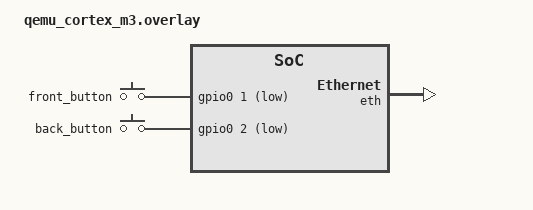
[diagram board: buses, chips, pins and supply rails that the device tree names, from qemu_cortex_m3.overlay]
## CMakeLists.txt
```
# SPDX-License-Identifier: Apache-2.0

cmake_minimum_required(VERSION 3.20.0)

set(ZEPHYR_EXTRA_MODULES "${CMAKE_CURRENT_SOURCE_DIR}/camera_service/")

find_package(Zephyr REQUIRED HINTS $ENV{ZEPHYR_BASE})

project(projeto_radar)

zephyr_include_directories(include/)

list(APPEND ZEPHYR_EXTRA_MODULES ${CMAKE_CURRENT_SOURCE_DIR}/src)

target_sources(app PRIVATE src/main.c src/display.c src/sensor.c src/system_thread.c)
```

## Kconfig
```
menu "Zephyr"
  source "Kconfig.zephyr"
endmenu

config DUMMY_DISPLAY
	bool "Dummy display driver"
	default y
	depends on DT_HAS_ZEPHYR_DUMMY_DC_ENABLED
	help
	  Enable dummy display driver compliant with display driver API.

menu "dev"
  config SIM_CAR_PASSAGE
      bool "Simular passagem de carro"
      default y
      help
        Habilita a simulação de passagem de carro.

  config TEST_SNTP
      bool "Testar SNTP"
      default n
      help
        Habilita o teste do SNTP.

  config SNTP_SERVER_ADDRESS
    string "SNTP server address"
    default "a.st1.ntp.br"

  config SNTP_SERVER_PORT
    int "SNTP server port"
    default 123

  config SNTP_SERVER_TIMEOUT_MS
    int "Duration to wait for response"
    default 1000

endmenu

menu "Radar Configuration"

  config RADAR_SENSOR_DISTANCE_MM
      int "Distância entre sensores (mm)"
      default 5000
      help
        Define a distância física em milímetros entre os dois sensores magnéticos.

  config RADAR_SPEED_LIMIT_KMH
      int "Limite de velocidade (km/h)"
      default 60
      help
        Define o limite de velocidade em km/h para detecção de infrações.

  config SIMULATE_PROCESSING_TIME
      bool "Simular tempo de processamento"
      default y
      help
        Habilita a simulação do tempo de processamento de componentes.
  
  config RADAR_PROCESSING_TIME_MS
      int "Tempo de processamento (ms)"
      default 500
      depends on SIMULATE_PROCESSING_TIME
      help
        Define o tempo de processamento em milissegundos para simulação.

endmenu
```

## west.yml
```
manifest:
  remotes:
    - name: zephyrproject-rtos
      url-base: https://github.com/zephyrproject-rtos
  projects:
    - name: zephyr
      remote: zephyrproject-rtos
      clone-depth: 1
      revision: v4.1.0
path: projeto_radar
```

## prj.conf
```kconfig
CONFIG_GPIO=y
CONFIG_ZBUS=y
CONFIG_DUMMY_DISPLAY=y
CONFIG_AUXDISPLAY=y
CONFIG_DISPLAY=y
CONFIG_ZBUS_MSG_SUBSCRIBER=y
CONFIG_QEMU_ICOUNT=n

CONFIG_CBPRINTF_FP_SUPPORT=y

# == RANDOM NUMBER GENERATOR ==
CONFIG_ENTROPY_GENERATOR=y
CONFIG_TEST_RANDOM_GENERATOR=y
# == == == == ==

CONFIG_LOG_BACKEND_UART=y
CONFIG_LOG=y
CONFIG_LOG_DEFAULT_LEVEL=3
CONFIG_LOG_MODE_DEFERRED=y
CONFIG_PRINTK=y

# ===== NETWORKING BASE =====
CONFIG_NETWORKING=y
CONFIG_NET_CONNECTION_MANAGER=y
CONFIG_NET_SOCKETS=y
CONFIG_NET_IPV4=y
CONFIG_NET_IPV6=y
CONFIG_NET_QEMU_ETHERNET=y
CONFIG_NET_QEMU_USER=y

# ===== NETWORK PROTOCOLS =====
CONFIG_NET_UDP=y
CONFIG_NET_TCP=y
CONFIG_SNTP=y
CONFIG_NET_SOCKETS_POLL_MAX=5

# ===== NETWORK INTERFACE CONFIGURATION =====
CONFIG_NET_CONFIG_SETTINGS=y
CONFIG_NET_CONFIG_AUTO_INIT=y
CONFIG_NET_CONFIG_NEED_IPV4=y
CONFIG_NET_DHCPV4=y
CONFIG_NET_DHCPV6=y
# CONFIG_NET_CONFIG_MY_IPV4_ADDR="192.168.0.100"
# CONFIG_NET_CONFIG_MY_IPV4_NETMASK="255.255.255.0"
# CONFIG_NET_CONFIG_MY_IPV4_GW="192.168.0.1"

# ===== ETHERNET CONFIGURATION =====
CONFIG_NET_L2_ETHERNET=y
CONFIG_ETH_STELLARIS=y
CONFIG_NET_SLIP_TAP=n

# ===== DNS CONFIGURATION =====
CONFIG_DNS_RESOLVER=y
CONFIG_DNS_SERVER_IP_ADDRESSES=y
CONFIG_DNS_SERVER1="8.8.8.8"

# ===== NETWORK BUFFERS =====
CONFIG_NET_BUF_RX_COUNT=16
CONFIG_NET_BUF_TX_COUNT=16
CONFIG_NET_PKT_RX_COUNT=16
CONFIG_NET_PKT_TX_COUNT=16
CONFIG_NET_CONTEXT_NET_PKT_POOL=y

# ===== NETWORK MANAGEMENT =====
CONFIG_NET_MGMT=y
CONFIG_NET_MGMT_EVENT=y
CONFIG_NET_MGMT_EVENT_INFO=y

# === CONFIG RETIRADA DO PROJETO SNTP CLIENT ===
# General config
# CONFIG_REQUIRES_FULL_LIBC=y
# CONFIG_POSIX_API=y




CONFIG_REQUIRES_FULL_LIBC=y

CONFIG_MAIN_STACK_SIZE=2048
# # Network debug config
# CONFIG_NET_LOG=y
# CONFIG_LOG=y
# CONFIG_NET_SOCKETS_LOG_LEVEL_DBG=n
# CONFIG_SNTP_LOG_LEVEL_DBG=n


# Habilite a interface Ethernet do QEMU
# CONFIG_NET_QEMU_ETHERNET=y
```

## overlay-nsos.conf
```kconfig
# Copyright (c) 2025 Embeint Inc

CONFIG_ETH_NATIVE_TAP=n
CONFIG_NET_DRIVERS=y
CONFIG_NET_SOCKETS=y
CONFIG_NET_SOCKETS_OFFLOAD=y
CONFIG_NET_NATIVE_OFFLOADED_SOCKETS=y
CONFIG_HEAP_MEM_POOL_SIZE=4096

# IPv6 DAD requires lower level network interface access, below exposed socket-level access
CONFIG_NET_IPV6_DAD=n
```

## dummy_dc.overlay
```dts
/*
 * Copyright (c) 2021 Nordic Semiconductor ASA
 *
 * SPDX-License-Identifier: Apache-2.0
 */

/ {
	chosen {
		zephyr,display = &dummy_dc;
	};

	dummy_dc: dummy_dc {
		compatible = "zephyr,dummy-dc";
		height = <240>;
		width = <320>;
	};
};
```

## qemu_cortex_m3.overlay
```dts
#include <zephyr/dt-bindings/gpio/gpio.h>

/ {
	
	aliases {
		sw0 = &front_button;
		sw1 = &back_button;
	};

	buttons {
		compatible = "gpio-keys";
		debounce-interval-ms = <30>;

		front_button: button_0 {
			gpios = <&gpio0 1 GPIO_ACTIVE_LOW>;
		};
		back_button: button_1 {
			gpios = <&gpio0 2 GPIO_ACTIVE_LOW>;
		};
	};

	chosen {
		zephyr,display = &dummy_dc;
	};

	dummy_dc: dummy_dc {
		compatible = "zephyr,dummy-dc";
		height = <240>;
		width = <320>;
		
	};


};

&gpio0 {
    status = "okay";
    compatible = "zephyr,gpio-emul";
    rising-edge;
    falling-edge;
    high-level;
    low-level;
    gpio-controller;
    #gpio-cells = < 0x2 >;
    phandle = < 0x1 >;
};

&eth {
    status = "okay";
};
```

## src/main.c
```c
#include "main.h"
#include "sensor.h"
#include "camera_service.h"
#include "display.h"

#include <stdio.h>
#include <zephyr/kernel.h>
#include <zephyr/logging/log.h>
#include <zephyr/zbus/zbus.h>
#include <string.h>
#include <zephyr/drivers/gpio/gpio_emul.h>
#include <zephyr/random/random.h>
#include <zephyr/drivers/auxdisplay.h>
#include <zephyr/device.h>

#ifdef CONFIG_SNTP
#include <zephyr/net/sntp.h>
#include <zephyr/net/socket.h>
#endif

LOG_MODULE_REGISTER(system);

#define SYSTEM_THREAD_STACK_SIZE 1024
#define NETWORK_THREAD_STACK_SIZE 1024

#define SYSTEM_THREAD_PRIORITY 2
#define NETWORK_THREAD_PRIORITY 4

K_THREAD_STACK_DEFINE(system_stack, SYSTEM_THREAD_STACK_SIZE);
K_THREAD_STACK_DEFINE(network_stack, NETWORK_THREAD_STACK_SIZE);

/*
    NTP to UTC Implementation by Matt
    at https://stackoverflow.com/questions/5206857/convert-ntp-timestamp-to-utc

    NTP_TIMESTAMP_DIFF - The difference in seconds between the NTP epoch (1900) and the Unix epoch (1970).
    NTP_MAX_INT_AS_DOUBLE - The maximum value of the fractional part of an NTP timestamp, which is 2^32 - 1.
*/
#define NTP_TIMESTAMP_DIFF     (2208988800)
#define NTP_MAX_INT_AS_DOUBLE  (4294967295.0)

#define TIMEZONE_OFFSET_SECONDS (-3 * 3600)

ZBUS_MSG_SUBSCRIBER_DEFINE(network_subscriber);
ZBUS_CHAN_ADD_OBS(network_chan, network_subscriber, 3);

/*
    @brief Converts SNTP time to a struct tm in Brazil's timezone and formats it as a string.
    @param tm_brazil Pointer to a struct tm to store the converted time.
    @param time_str Pointer to a string buffer to store the formatted time.
    @return 0 on success, negative error code on failure.
*/
int get_converted_sntp_time(struct tm *tm_brazil, char *time_str)
{
    struct sntp_time ts;
    int rc;
#ifdef CONFIG_SNTP_SERVER_ADDRESS
    const char *ntp_server = CONFIG_SNTP_SERVER_ADDRESS;
#else
    const char *ntp_server = "pool.ntp.org:123";
#endif

#ifdef CONFIG_SNTP_SERVER_TIMEOUT_MS
    const int timeout_ms = CONFIG_SNTP_SERVER_TIMEOUT_MS;
#else
    const int timeout_ms = 5000; 
#endif


    rc = sntp_simple(ntp_server, timeout_ms, &ts);
    if (rc == 0) {

        time_t unix_time;

        if (ts.seconds < NTP_TIMESTAMP_DIFF) {

            unix_time = (time_t)ts.seconds;
        } else {
            unix_time = (time_t)(ts.seconds - NTP_TIMESTAMP_DIFF);
        }       
        time_t datetime = unix_time + TIMEZONE_OFFSET_SECONDS;

        struct tm *_tm_brazil = gmtime(&datetime);
        if (_tm_brazil) {
            char _time_str[49];
            strftime(_time_str, 48, "[%Y-%m-%d %H:%M:%S]", _tm_brazil);

            if (time_str != NULL) {
                strcpy(time_str, _time_str);
                time_str[48] = '\0';
            }
            
            if (tm_brazil != NULL) {
                *tm_brazil = *_tm_brazil;
            }
            

            return 0;

        } else {
            return -1;
        }

    } else {
        return rc;
    }
}

static void network_thread(void *arg1, void *arg2, void *arg3) {
    ARG_UNUSED(arg1);
    ARG_UNUSED(arg2);
    ARG_UNUSED(arg3);

    while (1) {
        struct network_event_t data;
        const struct zbus_channel *chan;

        /*
            When the system thread identifies a violation, it will publish a request
            in the network channel.
        */
        if (!zbus_sub_wait_msg(&network_subscriber, &chan, &data, K_FOREVER)) {
            switch (data.type) {
                case NETWORK_EVENT_SNTP_REQUEST: {
                    struct tm tm_brazil;
                    char time_str[49];
                    int ret = get_converted_sntp_time(&tm_brazil, time_str);

                    data = (struct network_event_t) {
                        .type = NETWORK_EVENT_SNTP_RESPONSE,
                        .sntp_response = {
                            .unix_time = mktime(&tm_brazil),
                            .time_str = time_str,
                            .error_code = ret
                        }
                    };

                    int err = zbus_chan_pub(&network_chan, &data, K_NO_WAIT);

                    if (err) {
                        LOG_ERR("Failed to publish SNTP response: %d", err);
                    }

                    break;
                }
                
                default:
                    LOG_WRN("Unknown network event type: %d", data.type);
                    break;
            }
        }
    }
}

#if CONFIG_TEST_SNTP

void test_sntp(void)
{

    char time_str[49];
    int ret = get_converted_sntp_time(NULL, time_str);

    if (ret == 0) {
        LOG_INF("SNTP Converted Time: %s", time_str);
    } else {
        LOG_ERR("Failed to get SNTP time: %d", ret);
    }
    
}
#endif

void sim_car_pass(void)
{
    int random_delay = sys_rand32_get() % 300 + 100;

    LOG_INF("Delay aleatório: %d ms", random_delay);

    LOG_INF("Carro passando...");
    gpio_emul_input_set(sensor1.port, sensor1.pin, 1);
    k_msleep(2);
    gpio_emul_input_set(sensor1.port, sensor1.pin, 0);

    k_msleep(random_delay);

    gpio_emul_input_set(sensor2.port, sensor2.pin, 1);
    k_msleep(2);
    gpio_emul_input_set(sensor2.port, sensor2.pin, 0);

    LOG_INF("Carro passou!");
    k_msleep(300);
}

int main(void) {

    /*
    Waits for the system to be ready before starting simulation.
    */
    k_msleep(1000);

    LOG_INF("Sistema inicializado!");
    uint8_t sim_times = 5;

    while (1) {
#ifdef CONFIG_SIM_CAR_PASSAGE
        if (CONFIG_SIM_CAR_PASSAGE) {
            if (sim_times > 0) sim_car_pass();

            if (sim_times == 0) {
                break;
            }

            sim_times--;
        }
#endif
        #if CONFIG_TEST_SNTP
        test_sntp();
        #endif

        k_msleep(500);
    }
}

ZBUS_CHAN_DEFINE(network_chan, struct network_event_t, NULL, NULL, ZBUS_OBSERVERS_EMPTY, ZBUS_MSG_INIT(.type = NETWORK_EVENT_SNTP_RESPONSE, .sntp_response = {.unix_time = 0, .error_code = 0}));
K_THREAD_DEFINE(network_thread_id, SYSTEM_THREAD_STACK_SIZE, network_thread, NULL, NULL, NULL, SYSTEM_THREAD_PRIORITY, 0, 0);
```

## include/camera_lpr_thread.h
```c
#ifndef CAMERA_LPR_THREAD_H
#define CAMERA_LPR_THREAD_H

void camera_lpr_thread(void);

#endif // CAMERA_LPR_THREAD_H
```

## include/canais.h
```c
#ifndef CANAIS_H
#define CANAIS_H
#include <zephyr/zbus/zbus.h>

struct velocidade_evento_t {
    float velocidade_kmh;
    uint32_t event_id;
};

ZBUS_CHAN_DECLARE(velocidade_chan);

#endif
```

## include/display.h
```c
#ifndef _DISPLAY_H_
#define _DISPLAY_H_

#include <zephyr/zbus/zbus.h>

struct display_data_t {
    int brightness;
    int contrast;
    char text[128];
};

ZBUS_CHAN_DECLARE(display_chan);

#endif
```

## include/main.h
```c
#ifndef MAIN_H
#define MAIN_H

#include <zephyr/kernel.h>
#include <zephyr/zbus/zbus.h>
#include <time.h>

enum network_event_type {
    NETWORK_EVENT_SNTP_RESPONSE,
    NETWORK_EVENT_HTTP_RESPONSE,
    NETWORK_EVENT_SNTP_REQUEST,
    NETWORK_EVENT_HTTP_REQUEST,
    NETWORK_EVENT_ERROR,
};

struct network_event_t {
    enum network_event_type type;
    union {
        struct {
            time_t unix_time;
            char time_str[49];
            int error_code;
        } sntp_response;

        struct {
            int status_code;
            char *response;
        } http_response;

        struct {
            char *request_url;
            int timeout_ms;
        } http_request;
    };
};

int get_converted_sntp_time(struct tm *tm_brazil, char *time_str);

ZBUS_CHAN_DECLARE(network_chan);

#endif
```

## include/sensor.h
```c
#ifndef _SENSOR_H_
#define _SENSOR_H_

#include <stdint.h>
#include <zephyr/drivers/gpio.h>
#include <zephyr/zbus/zbus.h>

struct sensor_result {
    uint32_t timestamp_sensor1;
    uint32_t timestamp_sensor2;
    float velocidade_kmh;
};

// Torna sensor1 e sensor2 acessíveis globalmente
extern const struct gpio_dt_spec sensor1;
extern const struct gpio_dt_spec sensor2;

void sensor_thread(void *arg1, void *arg2, void *arg3);

// Função de cálculo de velocidade (pode ser usada em testes)
int calcular_velocidade_kmh(uint32_t t1_ms, uint32_t t2_ms, float distancia_m, float *velocidade_ptr);

struct velocidade_evento_t {
    float velocidade_kmh;
    uint32_t event_id;
};

struct sensor_evento_t {
    uint32_t timestamp_sensor1;
    uint32_t timestamp_sensor2;
};

ZBUS_CHAN_DECLARE(velocidade_chan);
ZBUS_CHAN_DECLARE(sensor_chan);

#endif
```

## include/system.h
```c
#ifndef SYSTEM_H
#define SYSTEM_H

void system_start(void);
void print_log(const char *message);
void init_threads(void);

#endif // SYSTEM_H
```

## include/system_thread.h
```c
#ifndef SYSTEM_THREAD_H
#define SYSTEM_THREAD_H

#include <time.h>


#define PLACA_BRASIL        "Brasil [LLL N L NN]"
#define PLACA_ARGENTINA     "Argentina [LL NNN LL]"
#define PLACA_PARAGUAI_CARRO "Paraguai (Carro) [LLLL NNN]"
#define PLACA_PARAGUAI_MOTO  "Paraguai (Moto) [NNN LLLL]"
#define PLACA_URUGUAI       "Uruguai [LLL NNNN]"
#define PLACA_BOLIVIA       "Bolivia [LL NNNNN]"

void system_thread(void *arg1, void *arg2, void *arg3);
bool validar_placa_mercosul(const char *placa, char *padrao);

#endif // SYSTEM_THREAD_H
```

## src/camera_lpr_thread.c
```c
#include <zephyr/kernel.h>
#include <zephyr/zbus/zbus.h>
#include <zephyr/sys/util.h>
#include <zephyr/logging/log.h>
#include "camera_lpr_thread.h"
#include <zephyr/random/random.h>

LOG_MODULE_REGISTER(camera_lpr);

// Definição dos canais ZBUS para trigger e resultado
ZBUS_CHAN_DEFINE(lpr_trigger_chan,         // nome do canal
                 int,                      // tipo de dado
                 NULL,                     // validator
                 NULL,                     // user_data
                 ZBUS_OBSERVERS_EMPTY,     // observers
                 ZBUS_MSG_INIT(0));        // valor inicial

struct lpr_result_t {
    char placa[16];
    char hash[32];
    bool valida;
};

ZBUS_CHAN_DEFINE(lpr_result_chan,
                 struct lpr_result_t,
                 NULL,
                 NULL,
                 ZBUS_OBSERVERS_EMPTY,
                 ZBUS_MSG_INIT(.placa = "", .hash = "", .valida = false));

#define LPR_STACK_SIZE 2048
#define LPR_PRIORITY 5

static void gerar_placa(char *placa, bool *valida) {
    uint32_t rand_val = sys_rand32_get();
    uint8_t fail_chance = rand_val % 100;
    if (fail_chance < CONFIG_RADAR_CAMERA_FAILURE_RATE_PERCENT) {
        // Placa inválida (falha simulada)
        placa[0] = '\0';
        *valida = false;
        LOG_INF("Falha simulada na câmera LPR");
        printk("Falha simulada na câmera LPR\n");
    } else {
        strcpy(placa, "BRA2E19"); // Exemplo Mercosul válida
        *valida = true;
    }
}

static void gerar_hash_foto(char *hash) {
    strcpy(hash, "HASH_PLACEHOLDER");
}

void camera_lpr_thread(void)
{
    while (1) {
        // Aguarda trigger via ZBUS
        int trigger;
        int ret = zbus_chan_read(&lpr_trigger_chan, &trigger, K_FOREVER);
        if (ret == 0 && trigger) {
            // Simula tempo de processamento caso habilitado
            if (CONFIG_SIMULATE_PROCESSING_TIME)
            {
                k_msleep(CONFIG_RADAR_PROCESSING_TIME_MS);
            }

            // Gera placa e hash
            char placa[16];
            char hash[32];
            bool valida;
            gerar_placa(placa, &valida);
            gerar_hash_foto(hash);

            struct {
                char placa[16];
                char hash[32];
                bool valida;
            } resultado;

            strcpy(resultado.placa, placa);
            strcpy(resultado.hash, hash);
            resultado.valida = valida;

            // Publica resultado no canal ZBUS
            zbus_chan_pub(&lpr_result_chan, &resultado, K_NO_WAIT);
        }
        // else: ignora triggers inválidos ou erros de leitura
    }
}

K_THREAD_DEFINE(camera_lpr_tid, LPR_STACK_SIZE, camera_lpr_thread, NULL, NULL, NULL, LPR_PRIORITY, 0, 0);
```

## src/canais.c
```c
#include <zephyr/zbus/zbus.h>
#include "canais.h"

// Inicializa o canal com zeros
ZBUS_CHAN_DEFINE(velocidade_chan, struct velocidade_evento_t, NULL, NULL, ZBUS_OBSERVERS_EMPTY, ZBUS_MSG_INIT(.velocidade_kmh = 0.0f, .event_id = 0));
```

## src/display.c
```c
#include "display.h"

#include <zephyr/kernel.h>
#include <zephyr/logging/log.h>
#include <zephyr/zbus/zbus.h>
#include <zephyr/drivers/auxdisplay.h>
// #include <zephyr/drivers/display.h>
#include <zephyr/device.h>
#include <stdio.h>
#include <string.h>

LOG_MODULE_REGISTER(display);

#define DISPLAY_THREAD_STACK_SIZE 2048
#define DISPLAY_THREAD_PRIORITY 4

K_THREAD_STACK_DEFINE(display_stack, DISPLAY_THREAD_STACK_SIZE);

ZBUS_MSG_SUBSCRIBER_DEFINE(display_subscriber);
ZBUS_CHAN_ADD_OBS(display_chan, display_subscriber, 3);

static void display_thread(void *arg1, void *arg2, void *arg3) {
    int rc;
    const struct device *const dev = DEVICE_DT_GET(DT_NODELABEL(dummy_dc));

    if (!device_is_ready(dev)) {
        LOG_ERR("Auxdisplay device is not ready.");
    }

    rc = auxdisplay_cursor_set_enabled(dev, true);

    if (rc != 0) {
        LOG_ERR("Failed to enable cursor: %d", rc);
    }

    while (1) {
        struct display_data_t data;
        const struct zbus_channel *chan;
        if(!zbus_sub_wait_msg(&display_subscriber, &chan, &data, K_FOREVER)) {
            // rc = auxdisplay_write(dev, data.text, strlen(data.text));
            // if (rc != 0) {
            //     LOG_ERR("Failed to write data: %d", rc);
            // }
            LOG_INF("%s \t |brilho=%d, contraste=%d|", data.text, data.brightness, data.contrast);
        }
    }
}

K_THREAD_DEFINE(display_thread_id, DISPLAY_THREAD_STACK_SIZE, display_thread, NULL, NULL, NULL, DISPLAY_THREAD_PRIORITY, 0, 0);
ZBUS_CHAN_DEFINE(display_chan, struct display_data_t, NULL, NULL, ZBUS_OBSERVERS_EMPTY, ZBUS_MSG_INIT(.brightness = 100, .contrast = 50, .text = "Hello, World!"));
```

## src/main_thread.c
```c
#include "camera_service.h"
#include "sensor.h"
#include "display.h"

#include <zephyr/kernel.h>
#include <zephyr/zbus/zbus.h>
#include <zephyr/logging/log.h>
#include <stdio.h>
LOG_MODULE_REGISTER(main_thread);

#define MAIN_THREAD_STACK_SIZE 1024
#define MAIN_THREAD_PRIORITY 1


ZBUS_MSG_SUBSCRIBER_DEFINE(main_subscriber);
ZBUS_CHAN_ADD_OBS(velocidade_chan, main_subscriber, 3);

static bool validar_placa_mercosul(const char *placa, const char *padrao) {
    if (!placa) return false;

    // Remove espaços da string (cria uma cópia sem espaços)
    char placa_sem_espacos[16]; // tamanho suficiente para placa + \0
    int j = 0;
    for (int i = 0; placa[i] != '\0' && j < (int)(sizeof(placa_sem_espacos) - 1); i++) {
        if (placa[i] != ' ')
            placa_sem_espacos[j++] = placa[i];
    }
    placa_sem_espacos[j] = '\0';

    size_t len = strlen(placa_sem_espacos);

    // Brasil: LLLNLNN (ex: BRA1B23)
    if (len == 7 &&
        isalpha(placa_sem_espacos[0]) && isalpha(placa_sem_espacos[1]) && isalpha(placa_sem_espacos[2]) &&
        isdigit(placa_sem_espacos[3]) &&
        isalpha(placa_sem_espacos[4]) &&
        isdigit(placa_sem_espacos[5]) && isdigit(placa_sem_espacos[6])) {
        
        // retorna o tipo de padrão (LLLNLNN)
        if (padrao != NULL){
            strcpy(padrao, "LLLNLNN");
        }

        return true;
    }

    // Argentina/Paraguai: LLNNNLL (ex: AB123CD)
    if (len == 7 &&
        isalpha(placa_sem_espacos[0]) && isalpha(placa_sem_espacos[1]) &&
        isdigit(placa_sem_espacos[2]) && isdigit(placa_sem_espacos[3]) && isdigit(placa_sem_espacos[4]) &&
        isalpha(placa_sem_espacos[5]) && isalpha(placa_sem_espacos[6])) {

        // retorna o tipo de padrão (LLNNNLL)
        if (padrao != NULL){
            strcpy(padrao, "LLNNNLL");
        }
        return true;
    }

    // Argentina alternativa: LLLNNLL (ex: ABC12DE)
    if (len == 7 &&
        isalpha(placa_sem_espacos[0]) && isalpha(placa_sem_espacos[1]) && isalpha(placa_sem_espacos[2]) &&
        isdigit(placa_sem_espacos[3]) && isdigit(placa_sem_espacos[4]) &&
        isalpha(placa_sem_espacos[5]) && isalpha(placa_sem_espacos[6])) {
        
        // retorna o tipo de padrão (LLLNNLL)
        if (padrao != NULL){
            strcpy(padrao, "LLLNNLL");
        }
        return true;
    }

    return false;
}

static void main_thread(void *arg1, void *arg2, void *arg3) {
    struct velocidade_evento_t evento;
    const struct zbus_channel *chan;
    uint32_t last_event_id = 0;

    // Mensagem inicial para o display
    struct display_data_t display_msg = {
        .brightness = 100,
        .contrast = 50,
        .text = "Thread principal executando..."
    };
    zbus_chan_pub(&display_chan, &display_msg, K_NO_WAIT);

    LOG_INF("Thread principal executando...");

    // TODO [OK]: usar observer (message subscriber, zbus_sub_wait_msg)
    while (1) {
        if (!zbus_sub_wait_msg(&main_subscriber, &chan, &evento, K_FOREVER)) {
            const float limite = IS_ENABLED(CONFIG_RADAR_SPEED_LIMIT_KMH) ? CONFIG_RADAR_SPEED_LIMIT_KMH : 60.0f;

            if (evento.event_id != last_event_id && evento.velocidade_kmh > limite) {
                last_event_id = evento.event_id;

                // Mensagem de infração para o display
                snprintf(display_msg.text, sizeof(display_msg.text), "Infracao! Acionando camera...");
                zbus_chan_pub(&display_chan, &display_msg, K_NO_WAIT);

                LOG_INF("\t- Infração detectada! Acionando câmera...");
                int err = camera_api_capture(K_NO_WAIT);
                if (err) {
                    LOG_ERR("Falha ao acionar câmera via ZBUS!");
                } else {
                    // Espera resposta da câmera
                    struct msg_camera_evt evt;
                    int evt_ret = zbus_chan_read(&chan_camera_evt, &evt, K_MSEC(500));
                    char padrao[8] = "";

                    if (evt_ret == 0) {
                        if (evt.type == MSG_CAMERA_EVT_TYPE_DATA && evt.captured_data) {
                            // Envia placa capturada para o display
                            snprintf(display_msg.text, sizeof(display_msg.text), "Placa: %s", evt.captured_data->plate);
                            zbus_chan_pub(&display_chan, &display_msg, K_NO_WAIT);

                            // LOG_INF("\t- Camera: Placa capturada: %s", evt.captured_data->plate);

                            if (validar_placa_mercosul(evt.captured_data->plate, padrao)) {
                                snprintf(display_msg.text, sizeof(display_msg.text), "Placa valida (%s)", padrao);
                                zbus_chan_pub(&display_chan, &display_msg, K_NO_WAIT);

                                // LOG_INF("\t- Placa válida (%s)", padrao);
                            } else {
                                snprintf(display_msg.text, sizeof(display_msg.text), "Placa invalida!");
                                zbus_chan_pub(&display_chan, &display_msg, K_NO_WAIT);

                                LOG_WRN("\t- Placa inválida!");
                            }
                        } else if (evt.type == MSG_CAMERA_EVT_TYPE_ERROR) {
                            snprintf(display_msg.text, sizeof(display_msg.text), "Camera erro: %d", evt.error_code);
                            zbus_chan_pub(&display_chan, &display_msg, K_NO_WAIT);

                            LOG_ERR("\t- Camera: Erro ao capturar imagem, code: %d", evt.error_code);
                        } else {
                            snprintf(display_msg.text, sizeof(display_msg.text), "Camera: Evento desconhecido");
                            zbus_chan_pub(&display_chan, &display_msg, K_NO_WAIT);

                            LOG_WRN("\t- Camera: Evento desconhecido");
                        }
                    } else {
                        snprintf(display_msg.text, sizeof(display_msg.text), "Camera: Sem resposta");
                        zbus_chan_pub(&display_chan, &display_msg, K_NO_WAIT);

                        LOG_WRN("\t- Camera: Nenhuma resposta recebida");
                    }
                }
            }
        }
    }
}

K_THREAD_DEFINE(main_thread_id, MAIN_THREAD_STACK_SIZE, main_thread, NULL, NULL, NULL, MAIN_THREAD_PRIORITY, 0, 0);
```

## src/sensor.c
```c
#include "sensor.h"
#include <zephyr/kernel.h>
#include <zephyr/device.h>
#include <zephyr/drivers/gpio.h>
#include <zephyr/sys/printk.h>
#include <zephyr/logging/log.h>
#include <inttypes.h>
#include <zephyr/zbus/zbus.h>
#include <stdio.h> 

LOG_MODULE_REGISTER(sensor);

#define SENSOR1_NODE DT_ALIAS(sw0)
#define SENSOR2_NODE DT_ALIAS(sw1)

#if !DT_NODE_EXISTS(SENSOR1_NODE)
#error "Unsupported board: sw0 devicetree alias is not defined"
#endif
#if !DT_NODE_EXISTS(SENSOR2_NODE)
#error "Unsupported board: sw1 devicetree alias is not defined"
#endif

const struct gpio_dt_spec sensor1 = GPIO_DT_SPEC_GET(SENSOR1_NODE, gpios);
const struct gpio_dt_spec sensor2 = GPIO_DT_SPEC_GET(SENSOR2_NODE, gpios);

static struct gpio_callback sensor1_cb_data;
static struct gpio_callback sensor2_cb_data;

static volatile uint32_t timestamp_sensor1 = 0;
static volatile uint32_t timestamp_sensor2 = 0;
static volatile bool sensor1_activated = false;
static volatile bool sensor2_activated = false;


ZBUS_MSG_SUBSCRIBER_DEFINE(sensor_subscriber);
ZBUS_CHAN_ADD_OBS(sensor_chan, sensor_subscriber, 3);

static void sensor1_triggered(const struct device *dev, struct gpio_callback *cb, uint32_t pins) {
    ARG_UNUSED(dev);
    ARG_UNUSED(cb);
    if (!sensor1_activated) {
        timestamp_sensor1 = k_uptime_get_32();
        sensor1_activated = true;
        LOG_INF("Sensor 1 ativado em %" PRIu32, timestamp_sensor1);
    }
}

static void sensor2_triggered(const struct device *dev, struct gpio_callback *cb, uint32_t pins) {
    ARG_UNUSED(dev);
    ARG_UNUSED(cb);
    if (!sensor2_activated && sensor1_activated) {
        timestamp_sensor2 = k_uptime_get_32();
        sensor2_activated = true;
        LOG_INF("Sensor 2 ativado em %" PRIu32, timestamp_sensor2);

        struct sensor_evento_t evento = {
            .timestamp_sensor1 = timestamp_sensor1,
            .timestamp_sensor2 = timestamp_sensor2
        };

        zbus_chan_pub(&sensor_chan, &evento, K_NO_WAIT);
    }
}

/**
 * @brief Calculate speed in km/h based on sensor triggers
 * 
 * @param t1_ms Timestamp of first sensor trigger in milliseconds
 * @param t2_ms Timestamp of second sensor trigger in milliseconds
 * @param distancia_m Distance between sensors in meters
 * @param velocidade_ptr Pointer to store the calculated speed value
 * @return int 0 on success, negative error code otherwise
 */
int calcular_velocidade_kmh(uint32_t t1_ms, uint32_t t2_ms, float distancia_m, float *velocidade_ptr) 
{
    if (velocidade_ptr == NULL) {
        return -EINVAL;
    }

    uint32_t dticks = t2_ms - t1_ms;
    float dt = (float)dticks / 1000.0f;

    if (dt <= 0.0f) {
        *velocidade_ptr = 0.0f;
        return -ERANGE;
    }

    float velocidade_ms = distancia_m / dt;

    if (velocidade_ms < 0.0f){
        *velocidade_ptr = 0.0f;
        return -ERANGE;
    }

    *velocidade_ptr = velocidade_ms * 3.6f;
    return 0;
}

#define SENSOR_THREAD_STACK_SIZE 1024
#define SENSOR_THREAD_PRIORITY 2

void sensor_thread(void *arg1, void *arg2, void *arg3) {
    int ret;
    
    if (!device_is_ready(sensor1.port) || !device_is_ready(sensor2.port)) {
        LOG_ERR("GPIO dos sensores não está pronto");
        return;
    }
    
    ret = gpio_pin_configure_dt(&sensor1, GPIO_INPUT);
    if (ret != 0) {
        LOG_ERR("Erro %d ao configurar sensor1", ret);
        return;
    }
    ret = gpio_pin_configure_dt(&sensor2, GPIO_INPUT);
    if (ret != 0) {
        LOG_ERR("Erro %d ao configurar sensor2", ret);
        return;
    }
    
    ret = gpio_pin_interrupt_configure_dt(&sensor1, GPIO_INT_EDGE_RISING);
    if (ret != 0) {
        LOG_ERR("Erro %d ao configurar interrupção sensor1", ret);
        return;
    }
    ret = gpio_pin_interrupt_configure_dt(&sensor2, GPIO_INT_EDGE_RISING);
    if (ret != 0) {
        LOG_ERR("Erro %d ao configurar interrupção sensor2", ret);
        return;
    }
    
    gpio_init_callback(&sensor1_cb_data, sensor1_triggered, BIT(sensor1.pin));
    gpio_add_callback(sensor1.port, &sensor1_cb_data);
    gpio_init_callback(&sensor2_cb_data, sensor2_triggered, BIT(sensor2.pin));
    gpio_add_callback(sensor2.port, &sensor2_cb_data);

    LOG_INF("Thread de Sensores inicializada (aliases sw0 e sw1)");

    static uint32_t event_id = 0;

    while (1) {
        struct sensor_evento_t evento;
        const struct zbus_channel *chan;

        if(!zbus_sub_wait_msg(&sensor_subscriber, &chan, &evento, K_FOREVER)) {


            float distancia_m = 1.0f;
#ifdef CONFIG_RADAR_SENSOR_DISTANCE_MM
            distancia_m = CONFIG_RADAR_SENSOR_DISTANCE_MM / 1000.0f;
#endif

            if (evento.timestamp_sensor1 != 0 && evento.timestamp_sensor2 != 0) {
                float velocidade_kmh = 0.0f;
                int err = calcular_velocidade_kmh(evento.timestamp_sensor1, evento.timestamp_sensor2, distancia_m, &velocidade_kmh);

                /*
                    Only log velocity with printf if not in ztest mode
                */
#ifndef CONFIG_ZTEST
                uint32_t dticks = evento.timestamp_sensor2 - evento.timestamp_sensor1;
                printf("\t\t   <inf> [dist. %.2f] Tempo: %u ms, Velocidade: %.2f km/h\n", (double)distancia_m, dticks, (double)velocidade_kmh);
#endif
                if (err == 0) {
                    
                    /*
                        Publish the speed event to the velocidade_chan channel
                        with the calculated speed and a unique event ID.
                    */
                    struct velocidade_evento_t vel_evento = {
                        .velocidade_kmh = velocidade_kmh,
                        .event_id = ++event_id
                    };
                    zbus_chan_pub(&velocidade_chan, &vel_evento, K_NO_WAIT);
                }

                sensor1_activated = false;
                sensor2_activated = false;
            }
        }
    }
}


ZBUS_CHAN_DEFINE(velocidade_chan, struct velocidade_evento_t, NULL, NULL, ZBUS_OBSERVERS_EMPTY, ZBUS_MSG_INIT(.velocidade_kmh = 0.0f, .event_id = 0));
ZBUS_CHAN_DEFINE(sensor_chan, struct sensor_evento_t, NULL, NULL, ZBUS_OBSERVERS_EMPTY, ZBUS_MSG_INIT(.timestamp_sensor1 = 0, .timestamp_sensor2 = 0));


K_THREAD_DEFINE(sensor_tid, SENSOR_THREAD_STACK_SIZE, sensor_thread, NULL, NULL, NULL, SENSOR_THREAD_PRIORITY, 0, 0);
```
